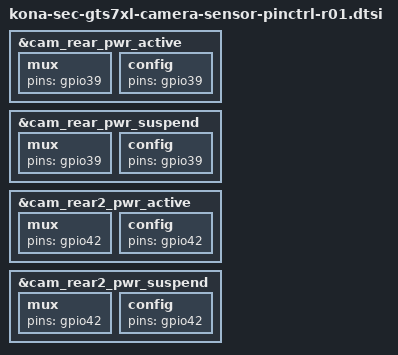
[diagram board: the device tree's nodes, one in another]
/* Copyright (c) 2016-2017, The Linux Foundation. All rights reserved.
 *
 * This program is free software; you can redistribute it and/or modify
 * it under the terms of the GNU General Public License version 2 and
 * only version 2 as published by the Free Software Foundation.
 *
 * This program is distributed in the hope that it will be useful,
 * but WITHOUT ANY WARRANTY; without even the implied warranty of
 * MERCHANTABILITY or FITNESS FOR A PARTICULAR PURPOSE.  See the
 * GNU General Public License for more details.
 */

#include "kona-sec-gts7xl-camera-sensor-pinctrl-common.dtsi"

&cam_rear_pwr_active {
	mux {
		pins = "gpio39";
	};
	config {
		pins = "gpio39";
	};
};

&cam_rear_pwr_suspend {
	mux {
		pins = "gpio39";
	};
	config {
		pins = "gpio39";
	};
};

&cam_rear2_pwr_active {
	mux {
		pins = "gpio42";
	};
	config {
		pins = "gpio42";
	};
};

&cam_rear2_pwr_suspend {
	mux {
		pins = "gpio42";
	};
	config {
		pins = "gpio42";
	};
};
